VERSION "Created by Jacob Geigle"

NS_ :

BS_:

BU_:

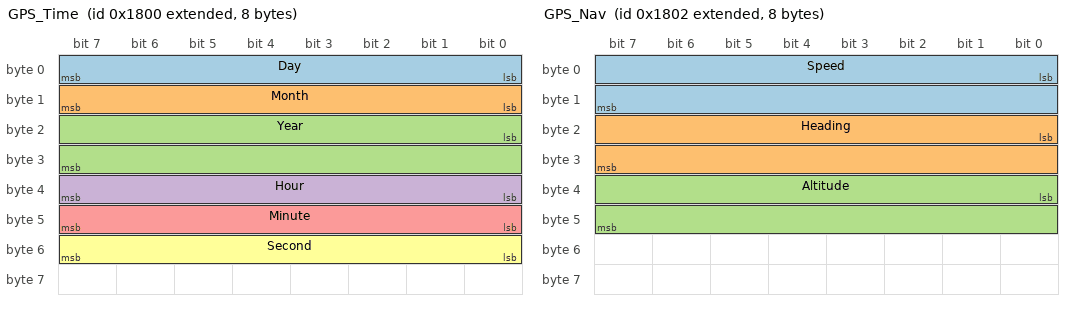
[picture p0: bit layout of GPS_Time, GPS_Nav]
BO_ 2147489792 GPS_Time: 8 GPS
  SG_ Day : 0|8@1+ (1,0) [1|31] "" TIME
  SG_ Month : 8|8@1+ (1,0) [1|12] "" TIME
  SG_ Year : 16|16@1+ (1,0) [1|65535] "" TIME
  SG_ Hour : 32|8@1+ (1,0) [0|23] "" TIME
  SG_ Minute : 40|8@1+ (1,0) [0|59] "" TIME
  SG_ Second : 48|8@1+ (1,0) [0|59] "" TIME

BO_ 2147489793 GPS_Loc: 8 GPS
  SG_ Lat_Decimal_Degrees : 0|32@1+ (0.000001,-90) [-90|90] "Deg" LOC
  SG_ Long_Decimal_Degrees : 32|32@1+ (0.000001,-180) [-180|180] "Deg" LOC

BO_ 2147489794 GPS_Nav: 8 GPS
  SG_ Speed : 0|16@1+ (0.1,0) [0|65535] "km/h" NAV
  SG_ Heading : 16|16@1+ (0.1,0) [0|3599] "Deg" NAV
  SG_ Altitude : 32|16@1+ (1,0) [0|65535] "m" LOC

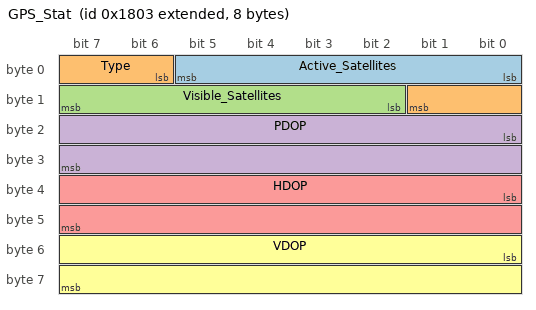
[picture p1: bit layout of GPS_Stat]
BO_ 2147489795 GPS_Stat: 8 GPS
  SG_ Active_Satellites : 0|6@1+ (1,0) [0|63] "" STAT
  SG_ Type : 6|4@1+ (1,0) [0|15] "" STAT
  SG_ Visible_Satellites : 10|6@1+ (1,0) [0|63] "" STAT
  SG_ PDOP : 16|16@1+ (0.1,0) [0|9999] "m" STAT
  SG_ HDOP : 32|16@1+ (0.1,0) [0|9999] "m" STAT
  SG_ VDOP : 48|16@1+ (0.1,0) [0|9999] "m" STAT

VAL_ 2147489795 Type 1 "No Fix" 2 "2D Fix" 3 "3D Fix" ;

BA_DEF_ BO_ "GenMsgCycleTime" INT 0 0;

BA_DEF_DEF_ "GenMsgCycleTime" 0;
BA_ "GenMsgCycleTime" BO_ 2147489792 1000;
BA_ "GenMsgCycleTime" BO_ 2147489793 1000;
BA_ "GenMsgCycleTime" BO_ 2147489794 1000;
BA_ "GenMsgCycleTime" BO_ 2147489795 1000;

BA_DEF_ BO_ "GenMsgDelayTime" INT 0 0;

BA_DEF_DEF_ "GenMsgDelayTime" 0;
BA_ "GenMsgDelayTime" BO_ 2147489792 300;
BA_ "GenMsgDelayTime" BO_ 2147489793 300;
BA_ "GenMsgDelayTime" BO_ 2147489794 300;
BA_ "GenMsgDelayTime" BO_ 2147489795 300;
